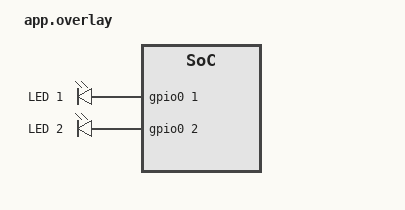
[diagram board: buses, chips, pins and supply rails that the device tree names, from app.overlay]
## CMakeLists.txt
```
# SPDX-License-Identifier: Apache-2.0

cmake_minimum_required(VERSION 3.28.0)

find_package(Zephyr REQUIRED HINTS $ENV{ZEPHYR_BASE})
project(projeto)

target_sources(app PRIVATE
	src/main.c
	src/led.c
)

target_include_directories(app PRIVATE src)
```

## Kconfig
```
# SPDX-License-Identifier: Apache-2.0

mainmenu "LED Module Application"

menu "LED Module Configuration"

config LED_PERIOD_SLOW_MS
	int "Period for SLOW pattern (ms)"
	default 1000
	range 10 100000
	help
	  Blink period for the slow pattern in milliseconds.

config LED_PERIOD_NORMAL_MS
	int "Period for NORMAL pattern (ms)"
	default 500
	range 10 100000
	help
	  Blink period for the normal pattern in milliseconds.

config LED_PERIOD_FAST_MS
	int "Period for FAST pattern (ms)"
	default 200
	range 10 100000
	help
	  Blink period for the fast pattern in milliseconds.

module = LED
module-str = led
source "subsys/logging/Kconfig.template.log_config"

endmenu

source "Kconfig.zephyr"
```

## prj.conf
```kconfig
CONFIG_GPIO=y
CONFIG_LOG=y
CONFIG_LED_LOG_LEVEL_DBG=y
```

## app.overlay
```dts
/*
 * SPDX-License-Identifier: Apache-2.0
 */

/ {
	aliases {
		led0 = &led0;
		led1 = &led1;
		led2 = &led2;
	};

	leds {
		compatible = "gpio-leds";
		led1: led_1 {
			gpios = <&gpio0 1 GPIO_ACTIVE_HIGH>;
			label = "LED 1";
		};
		led2: led_2 {
			gpios = <&gpio0 2 GPIO_ACTIVE_HIGH>;
			label = "LED 2";
		};
	};
};
```

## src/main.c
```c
// SPDX-License-Identifier: Apache-2.0

#include "led.h"
#include <zephyr/kernel.h>
#include <zephyr/logging/log.h>

LOG_MODULE_REGISTER(main, LOG_LEVEL_INF);

int main(void)
{
	int ret;
	size_t count;

	LOG_INF("Starting LED Controller Application on %s", CONFIG_BOARD);

	ret = led_init();
	if (ret < 0) {
		LOG_ERR("LED initialization failed: %d", ret);
		return ret;
	}

	count = led_get_count();
	LOG_INF("Initialized %u LEDs successfully", (unsigned int)count);

	/* Start LED 0 blinking SLOW */
	ret = led_blink(0, LED_PATTERN_SLOW);
	if (ret < 0) {
		LOG_ERR("Failed to start blink on LED 0: %d", ret);
	} else {
		LOG_INF("LED 0 configured to blink SLOW");
	}

	/* Start LED 1 blinking FAST */
	if (count > 1) {
		ret = led_blink(1, LED_PATTERN_FAST);
		if (ret < 0) {
			LOG_ERR("Failed to start blink on LED 1: %d", ret);
		} else {
			LOG_INF("LED 1 configured to blink FAST");
		}
	}

	/* Start LED 2 blinking NORMAL if present */
	if (count > 2) {
		ret = led_blink(2, LED_PATTERN_NORMAL);
		if (ret < 0) {
			LOG_ERR("Failed to start blink on LED 2: %d", ret);
		} else {
			LOG_INF("LED 2 configured to blink NORMAL");
		}
	}

	LOG_INF("All LEDs running independently with a single kernel timer.");

	while (1) {
		k_sleep(K_FOREVER);
	}

	return 0;
}
```

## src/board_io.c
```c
/*
 * SPDX-License-Identifier: Apache-2.0
 */

#include "board_io.h"

#include <zephyr/drivers/gpio.h>
#include <zephyr/kernel.h>
#include <zephyr/logging/log.h>

LOG_MODULE_REGISTER(board_io, CONFIG_LOG_DEFAULT_LEVEL);

#define LED0_NODE DT_ALIAS(led0)
#define SW0_NODE  DT_ALIAS(sw0)

static const struct gpio_dt_spec led = GPIO_DT_SPEC_GET(LED0_NODE, gpios);
static const struct gpio_dt_spec btn = GPIO_DT_SPEC_GET(SW0_NODE, gpios);

static bool s_led_state;

int board_io_init(void)
{
	int ret;

	if (!gpio_is_ready_dt(&led)) {
		LOG_ERR("Dispositivo GPIO para led0 nao esta pronto");
		return -ENODEV;
	}

	ret = gpio_pin_configure_dt(&led, GPIO_OUTPUT_INACTIVE);
	if (ret < 0) {
		LOG_ERR("Falha ao configurar pino do LED (%d)", ret);
		return ret;
	}
	s_led_state = false;

	if (!gpio_is_ready_dt(&btn)) {
		LOG_ERR("Dispositivo GPIO para sw0 nao esta pronto");
		return -ENODEV;
	}

	ret = gpio_pin_configure_dt(&btn, GPIO_INPUT);
	if (ret < 0) {
		LOG_ERR("Falha ao configurar pino do botao (%d)", ret);
		return ret;
	}

	return 0;
}

int board_led_set(bool on)
{
	int ret;

	ret = gpio_pin_set_dt(&led, on ? 1 : 0);
	if (ret < 0) {
		return ret;
	}

	s_led_state = on;
	return 0;
}

int board_led_get(void)
{
	return s_led_state ? 1 : 0;
}

int board_btn_read(void)
{
	int val = gpio_pin_get_dt(&btn);

	if (val < 0) {
		return val;
	}

	return val > 0 ? 1 : 0;
}
```

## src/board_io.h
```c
/*
 * SPDX-License-Identifier: Apache-2.0
 */

#ifndef BOARD_IO_H_
#define BOARD_IO_H_

#include <stdbool.h>

/**
 * @brief Inicializa os pinos de GPIO do LED e do botao via Devicetree.
 *
 * @return 0 em caso de sucesso, codigo de erro negativo caso contrario.
 */
int board_io_init(void);

/**
 * @brief Altera o estado do LED (led0).
 *
 * @param on true para ligar, false para desligar.
 * @return 0 em caso de sucesso, codigo de erro negativo caso contrario.
 */
int board_led_set(bool on);

/**
 * @brief Consulta o estado atual do LED.
 *
 * @return 1 se ligado, 0 se desligado, codigo de erro negativo caso contrario.
 */
int board_led_get(void);

/**
 * @brief Le o estado do botao (sw0).
 *
 * @return 1 se pressionado/ativo, 0 se solto/inativo, negativo em erro.
 */
int board_btn_read(void);

#endif /* BOARD_IO_H_ */
```

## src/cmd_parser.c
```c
/*
 * SPDX-License-Identifier: Apache-2.0
 */

#include "cmd_parser.h"

#include <ctype.h>
#include <errno.h>
#include <stdio.h>
#include <string.h>
#include <strings.h>

static const struct cmd_entry *cmd_table;
static size_t cmd_table_count;

void cmd_line_init(struct cmd_line_ctx *ctx)
{
	if (ctx == NULL) {
		return;
	}
	ctx->len = 0;
	ctx->overflow = false;
	ctx->last_was_cr = false;
	ctx->buf[0] = '\0';
}

cmd_feed_res_t cmd_line_feed(struct cmd_line_ctx *ctx, char c, char *out_line, size_t out_line_len)
{
	if (ctx == NULL) {
		return CMD_FEED_IGNORED;
	}

	/* Tratamento de LF apos CR (CRLF) */
	if (ctx->last_was_cr && c == '\n') {
		ctx->last_was_cr = false;
		return CMD_FEED_IGNORED;
	}
	ctx->last_was_cr = (c == '\r');

	/* Fim de linha */
	if (c == '\r' || c == '\n') {
		if (ctx->overflow) {
			ctx->len = 0;
			ctx->overflow = false;
			ctx->buf[0] = '\0';
			return CMD_FEED_OVERFLOW;
		}

		if (out_line != NULL && out_line_len > 0) {
			strncpy(out_line, ctx->buf, out_line_len - 1);
			out_line[out_line_len - 1] = '\0';
		}

		ctx->len = 0;
		ctx->buf[0] = '\0';
		return CMD_FEED_COMPLETE;
	}

	/* Backspace (0x08 = BS, 0x7F = DEL) */
	if (c == 0x08 || c == 0x7F) {
		if (ctx->overflow) {
			return CMD_FEED_IGNORED;
		}
		if (ctx->len > 0) {
			ctx->len--;
			ctx->buf[ctx->len] = '\0';
			return CMD_FEED_BACKSPACE;
		}
		return CMD_FEED_IGNORED;
	}

	/* Ignora caracteres de controle que nao sejam espaco/caracteres imprimiveis */
	if ((unsigned char)c < 32 || (unsigned char)c == 127) {
		return CMD_FEED_IGNORED;
	}

	/* Caractere normal */
	if (ctx->len < CONFIG_CMD_BUFFER_SIZE) {
		ctx->buf[ctx->len++] = c;
		ctx->buf[ctx->len] = '\0';
		return CMD_FEED_CONTINUE;
	} else {
		ctx->overflow = true;
		return CMD_FEED_IGNORED;
	}
}

int cmd_parser_init(const struct cmd_entry *table, size_t count)
{
	cmd_table = table;
	cmd_table_count = count;
	return 0;
}

int cmd_parser_process(const char *line, char *out_buf, size_t out_buf_len)
{
	if (out_buf == NULL || out_buf_len == 0) {
		return -EINVAL;
	}

	out_buf[0] = '\0';

	if (line == NULL) {
		return 0;
	}

	if (strlen(line) > CONFIG_CMD_BUFFER_SIZE) {
		snprintf(out_buf, out_buf_len, "ERR: line too long");
		return -EINVAL;
	}

	/* Pula espacos iniciais */
	const char *p = line;

	while (*p == ' ') {
		p++;
	}

	if (*p == '\0') {
		/* Linha vazia nao gera resposta de erro */
		return 0;
	}

	/* Extrai o verbo (comando) */
	const char *verb_start = p;

	while (*p != '\0' && *p != ' ') {
		p++;
	}
	size_t verb_len = p - verb_start;

	/* Extrai os argumentos, avancando apenas o espaco delimitador */
	const char *args = NULL;

	if (*p == ' ') {
		args = p + 1;
	}

	if (cmd_table != NULL) {
		for (size_t i = 0; i < cmd_table_count; i++) {
			if (cmd_table[i].name == NULL) {
				continue;
			}
			size_t name_len = strlen(cmd_table[i].name);

			if (verb_len == name_len &&
			    strncasecmp(verb_start, cmd_table[i].name, verb_len) == 0) {
				if (cmd_table[i].handler != NULL) {
					return cmd_table[i].handler(args, out_buf, out_buf_len);
				}
			}
		}
	}

	snprintf(out_buf, out_buf_len, "ERR: unknown command");
	return -ENOENT;
}
```

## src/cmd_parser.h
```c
/*
 * SPDX-License-Identifier: Apache-2.0
 */

#ifndef CMD_PARSER_H_
#define CMD_PARSER_H_

#include <stdbool.h>
#include <stddef.h>
#include <stdint.h>

#ifndef CONFIG_CMD_BUFFER_SIZE
#define CONFIG_CMD_BUFFER_SIZE 64
#endif

typedef int (*cmd_handler_t)(const char *args, char *out_buf, size_t out_buf_len);

struct cmd_entry {
	const char *name;
	cmd_handler_t handler;
};

typedef enum {
	CMD_FEED_CONTINUE = 0,
	CMD_FEED_COMPLETE,
	CMD_FEED_OVERFLOW,
	CMD_FEED_BACKSPACE,
	CMD_FEED_IGNORED
} cmd_feed_res_t;

struct cmd_line_ctx {
	char buf[CONFIG_CMD_BUFFER_SIZE + 1];
	size_t len;
	bool overflow;
	bool last_was_cr;
};

/**
 * @brief Inicializa o contexto de montagem de linha de comando.
 */
void cmd_line_init(struct cmd_line_ctx *ctx);

/**
 * @brief Processa um caractere recebido para acumulacao de linha, backspace e overflow.
 *
 * @param ctx Contexto da linha.
 * @param c Caractere recebido.
 * @param out_line Buffer de saida para a linha terminada (quando retorna CMD_FEED_COMPLETE).
 * @param out_line_len Capacidade do buffer de saida.
 * @return cmd_feed_res_t Acao resultante.
 */
cmd_feed_res_t cmd_line_feed(struct cmd_line_ctx *ctx, char c, char *out_line, size_t out_line_len);

/**
 * @brief Inicializa o despachante de comandos com a tabela de ponteiros de funcao.
 *
 * @param table Vetor de entradas de comandos.
 * @param count Quantidade de entradas no vetor.
 * @return 0 em caso de sucesso, negativo caso contrario.
 */
int cmd_parser_init(const struct cmd_entry *table, size_t count);

/**
 * @brief Processa uma linha de comando e escreve a resposta textual em out_buf.
 *
 * @param line Linha de entrada terminada em null (sem \\r ou \\n).
 * @param out_buf Buffer onde a resposta sera gravada.
 * @param out_buf_len Capacidade maxima do buffer de resposta.
 * @return 0 em caso de comando despachado com sucesso, ou codigo de erro.
 */
int cmd_parser_process(const char *line, char *out_buf, size_t out_buf_len);

#endif /* CMD_PARSER_H_ */
```

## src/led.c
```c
// SPDX-License-Identifier: Apache-2.0

#include "led.h"

#include <zephyr/drivers/gpio.h>
#include <zephyr/kernel.h>
#include <zephyr/logging/log.h>
#include <zephyr/sys/util.h>

LOG_MODULE_REGISTER(led, CONFIG_LED_LOG_LEVEL);

#ifndef CONFIG_LED_PERIOD_SLOW_MS
#define CONFIG_LED_PERIOD_SLOW_MS 1000
#endif

#ifndef CONFIG_LED_PERIOD_NORMAL_MS
#define CONFIG_LED_PERIOD_NORMAL_MS 500
#endif

#ifndef CONFIG_LED_PERIOD_FAST_MS
#define CONFIG_LED_PERIOD_FAST_MS 200
#endif

/*
 * Devicetree specifications for LEDs obtained from aliases led0, led1, ...
 */
static const struct gpio_dt_spec led_specs[] = {
#if DT_NODE_EXISTS(DT_ALIAS(led0))
	GPIO_DT_SPEC_GET(DT_ALIAS(led0), gpios),
#endif
#if DT_NODE_EXISTS(DT_ALIAS(led1))
	GPIO_DT_SPEC_GET(DT_ALIAS(led1), gpios),
#endif
#if DT_NODE_EXISTS(DT_ALIAS(led2))
	GPIO_DT_SPEC_GET(DT_ALIAS(led2), gpios),
#endif
#if DT_NODE_EXISTS(DT_ALIAS(led3))
	GPIO_DT_SPEC_GET(DT_ALIAS(led3), gpios),
#endif
#if DT_NODE_EXISTS(DT_ALIAS(led4))
	GPIO_DT_SPEC_GET(DT_ALIAS(led4), gpios),
#endif
#if DT_NODE_EXISTS(DT_ALIAS(led5))
	GPIO_DT_SPEC_GET(DT_ALIAS(led5), gpios),
#endif
#if DT_NODE_EXISTS(DT_ALIAS(led6))
	GPIO_DT_SPEC_GET(DT_ALIAS(led6), gpios),
#endif
#if DT_NODE_EXISTS(DT_ALIAS(led7))
	GPIO_DT_SPEC_GET(DT_ALIAS(led7), gpios),
#endif
};

#define LED_COUNT ARRAY_SIZE(led_specs)

BUILD_ASSERT(ARRAY_SIZE(led_specs) >= 2,
	     "Devicetree must define at least 2 LEDs (aliases led0, led1, ...)");

/*
 * Table-driven blink pattern periods (configured via Kconfig, no magic numbers)
 */
static const uint32_t pattern_periods_ms[LED_PATTERN_COUNT] = {
	[LED_PATTERN_SLOW] = CONFIG_LED_PERIOD_SLOW_MS,
	[LED_PATTERN_NORMAL] = CONFIG_LED_PERIOD_NORMAL_MS,
	[LED_PATTERN_FAST] = CONFIG_LED_PERIOD_FAST_MS,
};

/*
 * State operations interface (Table-driven pattern instead of switch/if-else on state)
 */
struct led_state_ops {
	void (*timer_tick)(int idx, int64_t now);
};

static void blink_timer_tick(int idx, int64_t now);

enum led_state {
	LED_STATE_OFF = 0,
	LED_STATE_ON,
	LED_STATE_BLINKING,
	LED_STATE_COUNT
};

static const struct led_state_ops state_ops[LED_STATE_COUNT] = {
	[LED_STATE_OFF] = {.timer_tick = NULL},
	[LED_STATE_ON] = {.timer_tick = NULL},
	[LED_STATE_BLINKING] = {.timer_tick = blink_timer_tick},
};

/*
 * Single multiplexed kernel timer for all LEDs.
 */
static struct k_timer led_timer;
static struct k_spinlock lock;

/*
 * State structure array indexed by LED ID
 */
static struct led_data led_states[LED_COUNT];

/*
 * Re-arm the single one-shot timer to the earliest upcoming deadline.
 * Must be called with lock held.
 */
static void rearm_timer_locked(int64_t now)
{
	int64_t earliest_deadline = INT64_MAX;
	bool has_blinking = false;

	for (size_t i = 0; i < LED_COUNT; i++) {
		if (led_states[i].is_blinking) {
			has_blinking = true;
			if (led_states[i].deadline_ticks < earliest_deadline) {
				earliest_deadline = led_states[i].deadline_ticks;
			}
		}
	}

	if (has_blinking && earliest_deadline != INT64_MAX) {
		int64_t diff = earliest_deadline - now;

		if (diff < 1) {
			diff = 1;
		}
		k_timer_start(&led_timer, K_TICKS(diff), K_NO_WAIT);
	} else {
		k_timer_stop(&led_timer);
	}
}

/*
 * Blink tick callback executed in ISR context. Short, no logs/printk.
 */
static void blink_timer_tick(int idx, int64_t now)
{
	if (now >= led_states[idx].deadline_ticks) {
		int64_t half_period_ticks = k_ms_to_ticks_ceil32(led_states[idx].period_ms / 2);

		gpio_pin_toggle_dt(&led_specs[idx]);
		led_states[idx].deadline_ticks += half_period_ticks;
		if (led_states[idx].deadline_ticks <= now) {
			led_states[idx].deadline_ticks = now + half_period_ticks;
		}
	}
}

/*
 * Timer ISR callback. Fast: processes ticks, computes deadlines, rearms timer.
 */
static void led_timer_callback(struct k_timer *timer)
{
	ARG_UNUSED(timer);

	k_spinlock_key_t key = k_spin_lock(&lock);
	int64_t now = k_uptime_ticks();

	for (size_t i = 0; i < LED_COUNT; i++) {
		if (led_states[i].ops != NULL && led_states[i].ops->timer_tick != NULL) {
			led_states[i].ops->timer_tick((int)i, now);
		}
	}

	rearm_timer_locked(now);

	k_spin_unlock(&lock, key);
}

/*
 * Command handlers (Command Pattern)
 */
typedef int (*led_cmd_fn)(int idx, void *arg);

static int cmd_turn_on(int idx, void *arg)
{
	ARG_UNUSED(arg);

	k_spinlock_key_t key = k_spin_lock(&lock);

	led_states[idx].ops = &state_ops[LED_STATE_ON];
	led_states[idx].is_blinking = false;
	rearm_timer_locked(k_uptime_ticks());
	k_spin_unlock(&lock, key);

	return gpio_pin_set_dt(&led_specs[idx], 1);
}

static int cmd_turn_off(int idx, void *arg)
{
	ARG_UNUSED(arg);

	k_spinlock_key_t key = k_spin_lock(&lock);

	led_states[idx].ops = &state_ops[LED_STATE_OFF];
	led_states[idx].is_blinking = false;
	rearm_timer_locked(k_uptime_ticks());
	k_spin_unlock(&lock, key);

	return gpio_pin_set_dt(&led_specs[idx], 0);
}

static int cmd_toggle(int idx, void *arg)
{
	ARG_UNUSED(arg);

	k_spinlock_key_t key = k_spin_lock(&lock);

	led_states[idx].ops = &state_ops[LED_STATE_OFF];
	led_states[idx].is_blinking = false;
	rearm_timer_locked(k_uptime_ticks());
	k_spin_unlock(&lock, key);

	return gpio_pin_toggle_dt(&led_specs[idx]);
}

static int cmd_blink(int idx, void *arg)
{
	enum led_pattern pattern = (enum led_pattern)(intptr_t)arg;
	uint32_t period = pattern_periods_ms[pattern];
	int64_t half_period_ticks = k_ms_to_ticks_ceil32(period / 2);

	k_spinlock_key_t key = k_spin_lock(&lock);
	int64_t now = k_uptime_ticks();

	led_states[idx].ops = &state_ops[LED_STATE_BLINKING];
	led_states[idx].is_blinking = true;
	led_states[idx].pattern = pattern;
	led_states[idx].period_ms = period;
	led_states[idx].deadline_ticks = now + half_period_ticks;

	rearm_timer_locked(now);
	k_spin_unlock(&lock, key);

	return gpio_pin_set_dt(&led_specs[idx], 1);
}

static const led_cmd_fn cmd_table[LED_ACTION_COUNT] = {
	[LED_ACTION_ON] = cmd_turn_on,
	[LED_ACTION_OFF] = cmd_turn_off,
	[LED_ACTION_TOGGLE] = cmd_toggle,
	[LED_ACTION_BLINK] = cmd_blink,
};

int led_init(void)
{
	k_spinlock_key_t key = k_spin_lock(&lock);

	k_timer_stop(&led_timer);
	k_spin_unlock(&lock, key);

	for (size_t i = 0; i < LED_COUNT; i++) {
		if (!gpio_is_ready_dt(&led_specs[i])) {
			LOG_ERR("GPIO controller for LED %u not ready", (unsigned int)i);
			return -ENODEV;
		}
	}

	for (size_t i = 0; i < LED_COUNT; i++) {
		int ret = gpio_pin_configure_dt(&led_specs[i], GPIO_OUTPUT_INACTIVE);

		if (ret < 0) {
			LOG_ERR("Failed to configure GPIO for LED %u: %d", (unsigned int)i, ret);
			return ret;
		}
	}

	key = k_spin_lock(&lock);
	for (size_t i = 0; i < LED_COUNT; i++) {
		led_states[i].ops = &state_ops[LED_STATE_OFF];
		led_states[i].is_blinking = false;
		led_states[i].pattern = (enum led_pattern)0;
		led_states[i].period_ms = 0;
		led_states[i].deadline_ticks = 0;
	}
	k_timer_init(&led_timer, led_timer_callback, NULL);
	k_spin_unlock(&lock, key);

	LOG_INF("LED module initialized successfully (%u LEDs)", (unsigned int)LED_COUNT);
	return 0;
}

int led_apply_action(int led_id, enum led_action action, void *arg)
{
	led_cmd_fn handler;

	if (action < 0 || action >= LED_ACTION_COUNT) {
		LOG_ERR("Invalid action: %d", action);
		return -EINVAL;
	}

	if (led_id != LED_ID_ALL && (led_id < 0 || led_id >= (int)LED_COUNT)) {
		LOG_ERR("Invalid LED ID: %d (LED count: %u)", led_id, (unsigned int)LED_COUNT);
		return -EINVAL;
	}

	handler = cmd_table[action];

	if (led_id == LED_ID_ALL) {
		int ret = 0;

		for (int i = 0; i < (int)LED_COUNT; i++) {
			int err = handler(i, arg);

			if (err != 0 && ret == 0) {
				ret = err;
			}
		}
		return ret;
	}

	return handler(led_id, arg);
}

int led_on(int led_id)
{
	return led_apply_action(led_id, LED_ACTION_ON, NULL);
}

int led_off(int led_id)
{
	return led_apply_action(led_id, LED_ACTION_OFF, NULL);
}

int led_toggle(int led_id)
{
	return led_apply_action(led_id, LED_ACTION_TOGGLE, NULL);
}

int led_blink(int led_id, enum led_pattern pattern)
{
	if (pattern < 0 || pattern >= LED_PATTERN_COUNT) {
		LOG_ERR("Invalid blink pattern: %d", pattern);
		return -EINVAL;
	}

	return led_apply_action(led_id, LED_ACTION_BLINK, (void *)(intptr_t)pattern);
}

size_t led_get_count(void)
{
	return LED_COUNT;
}

const struct led_data *led_get_state(int led_id)
{
	if (led_id < 0 || led_id >= (int)LED_COUNT) {
		return NULL;
	}
	return &led_states[led_id];
}
```

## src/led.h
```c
/* SPDX-License-Identifier: Apache-2.0 */

#ifndef LED_H_
#define LED_H_

#include <errno.h>
#include <zephyr/drivers/gpio.h>
#include <zephyr/kernel.h>

#ifdef __cplusplus
extern "C" {
#endif

/**
 * @brief Special identifier to apply an action to all configured LEDs.
 */
#define LED_ID_ALL (-1)

/**
 * @brief Predefined blink patterns.
 */
enum led_pattern {
	LED_PATTERN_SLOW = 0,
	LED_PATTERN_NORMAL,
	LED_PATTERN_FAST,
	LED_PATTERN_COUNT
};

/**
 * @brief Command / Action identifiers for table-driven execution.
 */
enum led_action {
	LED_ACTION_ON = 0,
	LED_ACTION_OFF,
	LED_ACTION_TOGGLE,
	LED_ACTION_BLINK,
	LED_ACTION_COUNT
};

struct led_state_ops;

/**
 * @brief Individual LED state structure.
 *
 * Indexed by LED ID. Stores current pattern, period, next deadline,
 * and whether the LED is currently blinking.
 */
struct led_data {
	const struct led_state_ops *ops;
	enum led_pattern pattern;
	uint32_t period_ms;
	int64_t deadline_ticks;
	bool is_blinking;
};

/**
 * @brief Initialize the LED module.
 *
 * Verifies that all GPIO controllers are ready and configures all LEDs
 * as outputs in the OFF (inactive) state.
 * Safe to be called multiple times without corrupting the timer.
 *
 * @retval 0 On success.
 * @retval -ENODEV If any GPIO controller is not ready.
 * @retval Negative errno on pin configuration failure.
 */
int led_init(void);

/**
 * @brief Turn ON a LED (or all LEDs if id is LED_ID_ALL).
 *
 * Cancels any ongoing blink on the target LED(s).
 *
 * @param led_id 0-based LED index or LED_ID_ALL.
 * @retval 0 On success.
 * @retval -EINVAL If led_id is invalid.
 */
int led_on(int led_id);

/**
 * @brief Turn OFF a LED (or all LEDs if id is LED_ID_ALL).
 *
 * Cancels any ongoing blink on the target LED(s).
 *
 * @param led_id 0-based LED index or LED_ID_ALL.
 * @retval 0 On success.
 * @retval -EINVAL If led_id is invalid.
 */
int led_off(int led_id);

/**
 * @brief Toggle the state of a LED (or all LEDs if id is LED_ID_ALL).
 *
 * Cancels any ongoing blink on the target LED(s).
 *
 * @param led_id 0-based LED index or LED_ID_ALL.
 * @retval 0 On success.
 * @retval -EINVAL If led_id is invalid.
 */
int led_toggle(int led_id);

/**
 * @brief Start blinking a LED (or all LEDs if id is LED_ID_ALL) with chosen pattern.
 *
 * @param led_id 0-based LED index or LED_ID_ALL.
 * @param pattern One of the patterns from enum led_pattern.
 * @retval 0 On success.
 * @retval -EINVAL If led_id or pattern is invalid.
 */
int led_blink(int led_id, enum led_pattern pattern);

/**
 * @brief Dispatch any action to a single LED or all LEDs.
 *
 * Central dispatcher helper for single or all LEDs using the Command Pattern.
 *
 * @param led_id 0-based LED index or LED_ID_ALL.
 * @param action One of the actions from enum led_action.
 * @param arg Optional action argument (e.g., enum led_pattern for BLINK).
 * @retval 0 On success.
 * @retval -EINVAL If led_id or action is invalid.
 */
int led_apply_action(int led_id, enum led_action action, void *arg);

/**
 * @brief Get the number of LEDs defined in devicetree.
 *
 * @return Total number of available LEDs.
 */
size_t led_get_count(void);

/**
 * @brief Query the current state of a LED.
 *
 * @param led_id 0-based LED index.
 * @return Pointer to struct led_data, or NULL if led_id is invalid.
 */
const struct led_data *led_get_state(int led_id);

#ifdef __cplusplus
}
#endif

#endif /* LED_H_ */
```

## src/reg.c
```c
/*******************************************************************
 * @file reg.c
 *
 * @brief Implementação de manipulação de bits de registrador (Atividade-05).
 *******************************************************************/

#include "reg.h"

void reg_set_bit(uint8_t *reg, uint8_t bit)
{
	/* TODO (Atividade-05): setar o bit `bit` de *reg sem afetar os outros. */
}

void reg_clear_bit(uint8_t *reg, uint8_t bit)
{
	/* TODO (Atividade-05): limpar o bit `bit` de *reg sem afetar os outros. */
}

bool reg_read_bit(uint8_t reg, uint8_t bit)
{
	/* TODO (Atividade-05): retornar true se o bit `bit` de reg está setado. */
	return false;
}
```

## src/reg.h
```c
/*******************************************************************
 * @file reg.h
 *
 * @brief Interface de manipulação de bits de registrador (Atividade-05).
 *******************************************************************/

#ifndef REG_H_
#define REG_H_

#include <stdbool.h>
#include <stdint.h>

void reg_set_bit(uint8_t *reg, uint8_t bit);
void reg_clear_bit(uint8_t *reg, uint8_t bit);
bool reg_read_bit(uint8_t reg, uint8_t bit);

#endif /* REG_H_ */
```

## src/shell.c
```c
/*
 * SPDX-License-Identifier: Apache-2.0
 */

#include "cmd_parser.h"
#include "shell.h"
#include "uart_transport.h"

#include <zephyr/kernel.h>
#include <zephyr/logging/log.h>

LOG_MODULE_REGISTER(shell, CONFIG_LOG_DEFAULT_LEVEL);

#define SHELL_STACK_SIZE 2048
#define SHELL_PRIORITY   7

static void shell_thread_entry(void *p1, void *p2, void *p3);

K_THREAD_DEFINE(shell_thread_id, SHELL_STACK_SIZE, shell_thread_entry, NULL, NULL, NULL,
		SHELL_PRIORITY, 0, K_TICKS_FOREVER);

static void shell_thread_entry(void *p1, void *p2, void *p3)
{
	ARG_UNUSED(p1);
	ARG_UNUSED(p2);
	ARG_UNUSED(p3);

	struct cmd_line_ctx line_ctx;
	char line[CONFIG_CMD_BUFFER_SIZE + 1];
	char resp[256];
	uint8_t byte;

	cmd_line_init(&line_ctx);

	/* Envia o prompt inicial */
	uart_transport_send_str("> ");

	while (1) {
		if (uart_transport_read_byte(&byte, K_FOREVER) != 0) {
			continue;
		}

		cmd_feed_res_t res = cmd_line_feed(&line_ctx, (char)byte, line, sizeof(line));

		switch (res) {
		case CMD_FEED_CONTINUE:
			/* Eco do caractere */
			uart_transport_send_char((char)byte);
			break;

		case CMD_FEED_BACKSPACE:
			/* Apaga o ultimo caractere no terminal */
			uart_transport_send_str("\b \b");
			break;

		case CMD_FEED_OVERFLOW:
			/* Linha maior que o buffer: descartada por inteiro com ERR: line too long
			 */
			uart_transport_send_str("\r\nERR: line too long\r\n> ");
			break;

		case CMD_FEED_COMPLETE:
			uart_transport_send_str("\r\n");
			if (line[0] != '\0') {
				(void)cmd_parser_process(line, resp, sizeof(resp));
				if (resp[0] != '\0') {
					uart_transport_send_str(resp);
					uart_transport_send_str("\r\n");
				}
			}
			uart_transport_send_str("> ");
			break;

		case CMD_FEED_IGNORED:
		default:
			break;
		}
	}
}

int shell_init(void)
{
	k_thread_start(shell_thread_id);
	LOG_INF("Thread da mini-shell iniciada");
	return 0;
}
```

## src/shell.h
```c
/*
 * SPDX-License-Identifier: Apache-2.0
 */

#ifndef SHELL_H_
#define SHELL_H_

/**
 * @brief Inicializa e dispara a thread de execucao da mini-shell.
 *
 * @return 0 em caso de sucesso.
 */
int shell_init(void);

#endif /* SHELL_H_ */
```

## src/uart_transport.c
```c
/*
 * SPDX-License-Identifier: Apache-2.0
 */

#include "uart_transport.h"

#include <zephyr/drivers/uart.h>
#include <zephyr/kernel.h>
#include <zephyr/logging/log.h>

LOG_MODULE_REGISTER(uart_transport, CONFIG_LOG_DEFAULT_LEVEL);

#define UART_NODE DT_NODELABEL(uart1)

static const struct device *const uart_dev = DEVICE_DT_GET(UART_NODE);

K_MSGQ_DEFINE(uart_rx_msgq, sizeof(uint8_t), 128, 4);

static void uart_fifo_callback(const struct device *dev, void *user_data)
{
	ARG_UNUSED(user_data);

	uart_irq_update(dev);

	while (uart_irq_rx_ready(dev)) {
		uint8_t c;

		if (uart_fifo_read(dev, &c, 1) <= 0) {
			break;
		}

		/* A ISR apenas enfileira o byte, sem parsing */
		(void)k_msgq_put(&uart_rx_msgq, &c, K_NO_WAIT);
	}
}

int uart_transport_init(void)
{
	int ret;

	if (!device_is_ready(uart_dev)) {
		LOG_ERR("Dispositivo UART1 nao esta pronto");
		return -ENODEV;
	}

	ret = uart_irq_callback_user_data_set(uart_dev, uart_fifo_callback, NULL);
	if (ret < 0) {
		LOG_ERR("Falha ao registrar callback de interrupcao UART (%d)", ret);
		return ret;
	}

	uart_irq_rx_enable(uart_dev);
	LOG_INF("UART1 inicializada com sucesso em modo interrupcao");
	return 0;
}

int uart_transport_read_byte(uint8_t *byte, k_timeout_t timeout)
{
	if (byte == NULL) {
		return -EINVAL;
	}

	return k_msgq_get(&uart_rx_msgq, byte, timeout);
}

void uart_transport_send_char(char c)
{
	uart_poll_out(uart_dev, (unsigned char)c);
}

void uart_transport_send_str(const char *str)
{
	if (str == NULL) {
		return;
	}

	while (*str != '\0') {
		uart_transport_send_char(*str);
		str++;
	}
}
```

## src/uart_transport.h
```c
/*
 * SPDX-License-Identifier: Apache-2.0
 */

#ifndef UART_TRANSPORT_H_
#define UART_TRANSPORT_H_

#include <stdint.h>
#include <zephyr/kernel.h>

/**
 * @brief Inicializa a UART1 em modo interrupcao e configura a fila de RX.
 *
 * @return 0 em caso de sucesso, codigo negativo de erro caso contrario.
 */
int uart_transport_init(void);

/**
 * @brief Le um byte recebido da fila de recepcao da UART.
 *
 * @param byte Ponteiro onde o byte lido sera armazenado.
 * @param timeout Tempo limite de espera.
 * @return 0 se um byte foi lido, negativo em caso de timeout/erro.
 */
int uart_transport_read_byte(uint8_t *byte, k_timeout_t timeout);

/**
 * @brief Transmite um caractere pela UART1.
 *
 * @param c Caractere a ser transmitido.
 */
void uart_transport_send_char(char c);

/**
 * @brief Transmite uma string terminada em null pela UART1.
 *
 * @param str String a ser transmitida.
 */
void uart_transport_send_str(const char *str);

#endif /* UART_TRANSPORT_H_ */
```
